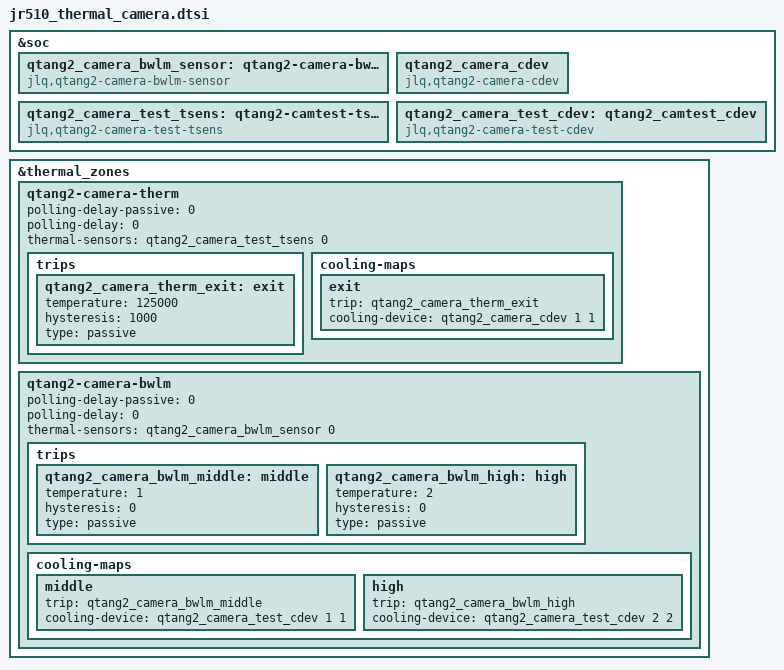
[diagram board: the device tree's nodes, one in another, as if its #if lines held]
// SPDX-License-Identifier: GPL-2.0+
//#define JLQ_CAMERA_THERMAL_TEST 1

&soc {
	qtang2_camera_bwlm_sensor: qtang2-camera-bwlm-sensor{
		compatible = "jlq,qtang2-camera-bwlm-sensor";
		#thermal-sensor-cells = <1>;
	};

	qtang2_camera_cdev: qtang2_camera_cdev{
		compatible = "jlq,qtang2-camera-cdev";
		#cooling-cells = <2>;
	};

#ifdef JLQ_CAMERA_THERMAL_TEST
	qtang2_camera_test_tsens: qtang2-camtest-tsens{
		compatible = "jlq,qtang2-camera-test-tsens";
		#thermal-sensor-cells = <1>;
	};

	qtang2_camera_test_cdev: qtang2_camtest_cdev{
		compatible = "jlq,qtang2-camera-test-cdev";
		#cooling-cells = <2>;
	};
#endif
};

&thermal_zones {
	qtang2-camera-therm {
		polling-delay-passive = <0>;
		polling-delay = <0>;
#ifdef JLQ_CAMERA_THERMAL_TEST
		thermal-sensors = <&qtang2_camera_test_tsens 0>;
#else
		thermal-sensors = <&qmi_sensor (QTANG_QMI_MODEM_INST_ID
								+QTANG_QMI_MODEM_TSENS_TZ_SENSOR2)>;
#endif
		trips {
			qtang2_camera_therm_exit: exit {
				temperature = <125000>;
				hysteresis = <1000>;
				type = "passive";
			};
		};
		cooling-maps {
			exit{
				trip = <&qtang2_camera_therm_exit>;
				cooling-device = <&qtang2_camera_cdev 1 1>;
			};
		};
	};

	qtang2-camera-bwlm {
		polling-delay-passive = <0>;
		polling-delay = <0>;
		thermal-sensors = <&qtang2_camera_bwlm_sensor 0>;
		trips {
			qtang2_camera_bwlm_middle: middle {
				temperature = <1>;
				hysteresis = <0>;
				type = "passive";
			};
			qtang2_camera_bwlm_high: high {
				temperature = <2>;
				hysteresis = <0>;
				type = "passive";
			};
		};
		cooling-maps {
#ifdef JLQ_CAMERA_THERMAL_TEST
			middle{
				trip = <&qtang2_camera_bwlm_middle>;
				cooling-device = <&qtang2_camera_test_cdev 1 1>;
			};
			high{
				trip = <&qtang2_camera_bwlm_high>;
				cooling-device = <&qtang2_camera_test_cdev 2 2>;
			};
#else
			middle{
				trip = <&qtang2_camera_bwlm_middle>;
				cooling-device = <&modem_proc 1 1>;
			};
			high{
				trip = <&qtang2_camera_bwlm_high>;
				cooling-device = <&modem_proc 2 2>;
			};
#endif
		};
	};
};
